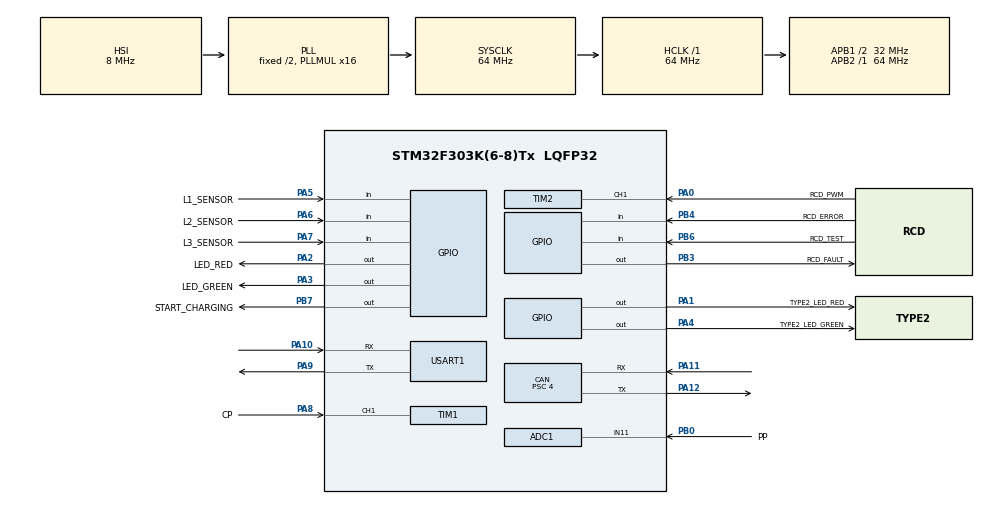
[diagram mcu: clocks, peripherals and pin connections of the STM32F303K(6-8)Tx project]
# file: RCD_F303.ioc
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ADC1.Channel-0\#ChannelRegularConversion=ADC_CHANNEL_11
ADC1.ContinuousConvMode=ENABLE
ADC1.NbrOfConversionFlag=1
ADC1.Offset-0\#ChannelRegularConversion=0
ADC1.OffsetNumber-0\#ChannelRegularConversion=ADC_OFFSET_NONE
ADC1.Rank-0\#ChannelRegularConversion=1
ADC1.SamplingTime-0\#ChannelRegularConversion=ADC_SAMPLETIME_4CYCLES_5
ADC1.SamplingTimeOPAMP-0\#ChannelRegularConversion=ADC_SAMPLETIME_7CYCLES_5
ADC1.SubFamily=STM32F303x8
ADC1.master=1
CAN.BS1=CAN_BS1_13TQ
CAN.BS2=CAN_BS2_2TQ
CAN.CalculateBaudRate=500000
CAN.CalculateTimeBit=2000
CAN.CalculateTimeQuantum=125.0
CAN.Prescaler=4
Mcu.Family=STM32F3
Mcu.Name=STM32F303K(6-8)Tx
Mcu.Package=LQFP32
NVIC.CAN_RX0_IRQn=true\:1\:0\:true\:false\:true\:true\:true\:true
NVIC.PriorityGroup=NVIC_PRIORITYGROUP_4
NVIC.TIM1_CC_IRQn=true\:0\:0\:false\:false\:true\:true\:true\:true
PA0.GPIO_Label=RCD_PWM
PA0.Signal=S_TIM2_CH1_ETR
PA1.GPIO_Label=TYPE2_LED_RED
PA1.Signal=GPIO_Output
PA10.Mode=Asynchronous
PA10.Signal=USART1_RX
PA11.Mode=CAN_Activate
PA11.Signal=CAN_RX
PA12.Mode=CAN_Activate
PA12.Signal=CAN_TX
PA2.GPIO_Label=LED_RED
PA2.Signal=GPIO_Output
PA3.GPIO_Label=LED_GREEN
PA3.Signal=GPIO_Output
PA4.GPIO_Label=TYPE2_LED_GREEN
PA4.Signal=GPIO_Output
PA5.GPIO_Label=L1_SENSOR
PA5.Signal=GPIO_Input
PA6.GPIO_Label=L2_SENSOR
PA6.Signal=GPIO_Input
PA7.GPIO_Label=L3_SENSOR
PA7.GPIO_PuPd=GPIO_NOPULL
PA7.Signal=GPIO_Input
PA8.GPIO_Label=CP
PA8.Signal=S_TIM1_CH1
PA9.Mode=Asynchronous
PA9.Signal=USART1_TX
PB0.GPIO_Label=PP
PB0.Mode=IN11-Single-Ended
PB0.Signal=ADC1_IN11
PB3.GPIO_Label=RCD_FAULT
PB3.GPIO_ModeDefaultOutputPP=GPIO_MODE_OUTPUT_OD
PB3.GPIO_PuPd=GPIO_NOPULL
PB3.PinState=GPIO_PIN_SET
PB3.Signal=GPIO_Output
PB4.GPIO_Label=RCD_ERROR
PB4.Signal=GPIO_Input
PB6.GPIO_Label=RCD_TEST
PB6.Signal=GPIO_Input
PB7.GPIO_Label=START_CHARGING
PB7.GPIO_PuPd=GPIO_PULLDOWN
PB7.Signal=GPIO_Output
ProjectManager.HeapSize=0x200
ProjectManager.StackSize=0x400
ProjectManager.TargetToolchain=STM32CubeIDE
RCC.AHBFreq_Value=64000000
RCC.APB1CLKDivider=RCC_HCLK_DIV2
RCC.APB1Freq_Value=32000000
RCC.APB1TimFreq_Value=64000000
RCC.APB2Freq_Value=64000000
RCC.APB2TimFreq_Value=64000000
RCC.CortexFreq_Value=64000000
RCC.HCLKFreq_Value=64000000
RCC.HSE_VALUE=8000000
RCC.HSI_VALUE=8000000
RCC.PLLMUL=RCC_PLL_MUL16
RCC.SYSCLKFreq_VALUE=64000000
RCC.SYSCLKSourceVirtual=RCC_SYSCLKSOURCE_PLLCLK
SH.S_TIM1_CH1.0=TIM1_CH1,PWM_Input_1
SH.S_TIM2_CH1_ETR.0=TIM2_CH1,PWM_Input_1
USART1.VirtualMode-Asynchronous=VM_ASYNC
VP_TIM1_VS_ClockSourceINT.Mode=Internal
VP_TIM2_VS_ClockSourceINT.Mode=Internal
board=custom

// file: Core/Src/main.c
/* USER CODE BEGIN Header */
/**
  ******************************************************************************
  * @file           : main.c
  * @brief          : Main program body
  ******************************************************************************
  * @attention
  *
  * Copyright (c) 2025 STMicroelectronics.
  * All rights reserved.
  *
  * This software is licensed under terms that can be found in the LICENSE file
  * in the root directory of this software component.
  * If no LICENSE file comes with this software, it is provided AS-IS.
  *
  ******************************************************************************
  */
/* USER CODE END Header */
#include "main.h"
#include "adc.h"
#include "can.h"
#include "tim.h"
#include "usart.h"
#include "gpio.h"

/* USER CODE BEGIN Includes */
#include "app.h"
/* USER CODE END Includes */

void SystemClock_Config(void);

int main(void)
{

  /* MCU Configuration--------------------------------------------------------*/

  /* Reset of all peripherals, Initializes the Flash interface and the Systick. */
  HAL_Init();

  /* Configure the system clock */
  SystemClock_Config();

  /* Initialize all configured peripherals */
  MX_GPIO_Init();
  MX_CAN_Init();
  MX_USART1_UART_Init();
  MX_ADC1_Init();
  MX_TIM2_Init();
  MX_TIM1_Init();
  /* USER CODE BEGIN 2 */

  app_main();
  /* USER CODE END 2 */

  /* Infinite loop */
  while (1)
  {

  }
}

void SystemClock_Config(void)
{
  RCC_OscInitTypeDef RCC_OscInitStruct = {0};
  RCC_ClkInitTypeDef RCC_ClkInitStruct = {0};
  RCC_PeriphCLKInitTypeDef PeriphClkInit = {0};

  /** Initializes the RCC Oscillators according to the specified parameters
  * in the RCC_OscInitTypeDef structure.
  */
  RCC_OscInitStruct.OscillatorType = RCC_OSCILLATORTYPE_HSI;
  RCC_OscInitStruct.HSIState = RCC_HSI_ON;
  RCC_OscInitStruct.HSICalibrationValue = RCC_HSICALIBRATION_DEFAULT;
  RCC_OscInitStruct.PLL.PLLState = RCC_PLL_ON;
  RCC_OscInitStruct.PLL.PLLSource = RCC_PLLSOURCE_HSI;
  RCC_OscInitStruct.PLL.PLLMUL = RCC_PLL_MUL16;
  if (HAL_RCC_OscConfig(&RCC_OscInitStruct) != HAL_OK)
  {
    Error_Handler();
  }

  /** Initializes the CPU, AHB and APB buses clocks
  */
  RCC_ClkInitStruct.ClockType = RCC_CLOCKTYPE_HCLK|RCC_CLOCKTYPE_SYSCLK
                              |RCC_CLOCKTYPE_PCLK1|RCC_CLOCKTYPE_PCLK2;
  RCC_ClkInitStruct.SYSCLKSource = RCC_SYSCLKSOURCE_PLLCLK;
  RCC_ClkInitStruct.AHBCLKDivider = RCC_SYSCLK_DIV1;
  RCC_ClkInitStruct.APB1CLKDivider = RCC_HCLK_DIV2;
  RCC_ClkInitStruct.APB2CLKDivider = RCC_HCLK_DIV1;

  if (HAL_RCC_ClockConfig(&RCC_ClkInitStruct, FLASH_LATENCY_2) != HAL_OK)
  {
    Error_Handler();
  }
  PeriphClkInit.PeriphClockSelection = RCC_PERIPHCLK_USART1|RCC_PERIPHCLK_TIM1
                              |RCC_PERIPHCLK_ADC12;
  PeriphClkInit.Usart1ClockSelection = RCC_USART1CLKSOURCE_PCLK1;
  PeriphClkInit.Adc12ClockSelection = RCC_ADC12PLLCLK_DIV1;
  PeriphClkInit.Tim1ClockSelection = RCC_TIM1CLK_HCLK;
  if (HAL_RCCEx_PeriphCLKConfig(&PeriphClkInit) != HAL_OK)
  {
    Error_Handler();
  }
}

void Error_Handler(void)
{
  /* USER CODE BEGIN Error_Handler_Debug */
	HAL_GPIO_TogglePin(LED_RED_GPIO_Port, LED_RED_Pin);
  /* User can add his own implementation to report the HAL error return state */
  __disable_irq();
  while (1)
  {
  }
  /* USER CODE END Error_Handler_Debug */
}
